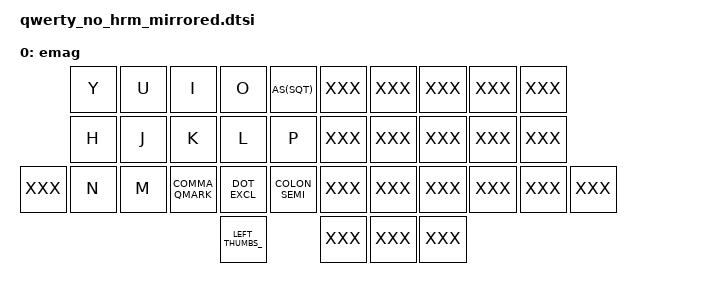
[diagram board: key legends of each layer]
/**
 * Alpha Layer - QWERTY (No Homerow Mods, Mirrored)
 */

/ {
	keymap {
    	compatible = "zmk,keymap";

    	emag {
      		display-name = "emag";
    		bindings = <
//                ╭─────────────┬─────────────┬─────────────┬─────────────┬─────────────╮   ╭─────────────┬─────────────┬─────────────┬─────────────┬─────────────╮
                   &kp Y         &kp U         &kp I         &kp O         AS(SQT)           XXX           XXX           XXX           XXX           XXX
//                ├─────────────┼─────────────┼─────────────┼─────────────┼─────────────┤   ├─────────────├─────────────┼─────────────┼─────────────┼─────────────┤
                   &kp H         &kp J         &kp K         &kp L         &kp P             XXX           XXX           XXX           XXX           XXX
//  ╭─────────────┬─────────────┼─────────────┼─────────────┼─────────────┼─────────────┤   ├─────────────├─────────────┼─────────────┼─────────────┼─────────────┬─────────────╮
     XXX           &kp N         &kp M         COMMA_QMARK   DOT_EXCL      COLON_SEMI        XXX           XXX           XXX           XXX           XXX           XXX
//  ╰─────────────┴─────────────┴─────────────┼─────────────┼─────────────┼─────────────┤   ├─────────────├─────────────┼─────────────┼─────────────┴─────────────┴─────────────╯
                                                             _LEFT_THUMBS_                   XXX           XXX           XXX
//                                            ╰─────────────┴─────────────┴─────────────╯   ╰─────────────┴─────────────┴─────────────╯
    		>;
		};
	};
};
